# SC32F10T_10G register map
File version: 1.0
CPU: CM0+ r0p1, little endian, MPU, no FPU, 4 interrupt priority bits
Registers are 32-bit, access not given, reset 0x0 unless marked. A register's access mark holds for its fields unless they carry their own. Offsets are from the block's base; [hi:lo] are bit positions.

## WDT
Base 0x40000330
0x0C WDT_CON rw — WDT控制寄存器
  [0] CLRWDT — WDT计数清零位该位通过软件写1，由硬件自动清0。0：无影响1： WDT计数器从0开始计数
0x10 WDT_CFG rw — WDT设置寄存器
  [2:0] WDTCKS — 看门狗时钟选择：WDTCKS[2:0]WDT溢出时间000500ms001250ms010125ms01162.5ms10031.5ms10115.75ms1107.88ms1113.94ms

## IAP
Base 0x400003C0
0x00 IAPKEY — 数据保护寄存器
0x04 IAP_SNB — IAP扇区编号设置寄存器
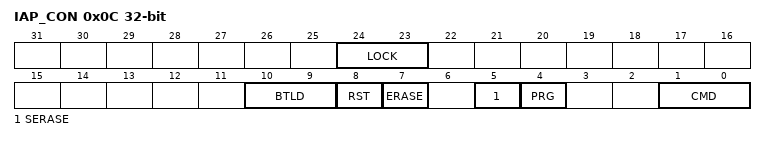
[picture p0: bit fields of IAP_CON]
0x0C IAP_CON rw — IAP控制寄存器
  [24:23] LOCK — 对该位写1后，IAP_CON 寄存器被锁定。当检测到解锁序列时，由硬件将该位清0。如果解锁操作失败，该位仍保持置 1，直到下一次系统复位。
  [10:9] BTLD — 软件复位后程序启动区域选择位：00：芯片软件复位后从APROM（主存储区）启动01：芯片软件复位后从LDROM（系统存储区）启动10：芯片软件复位后从嵌入式SRAM启动11：保留
  [8] RST — 软件复位控制位0：程序正常运行1：对该位写1后系统立刻复位
  [7] ERASE — 全擦（All Erase）控制位0：无操作1：对该位写1后再配置CMD[1:0]=10，则进入APROM全擦除操作，APROM将全部擦除
  [5] SERASE — 扇区擦除（Sector Erase）控制位0：无操作1：对该位写1后再配置CMD[1:0]=10，则进入APROM扇区擦除操作，APROM的指定Sector将被擦除
  [4] PRG — 编程（Program）控制位0：禁止 Flash 编程1：使能 Flash 编程
  [1:0] CMD — IAP命令使能控制位10：执行擦除操作命令其它 : 保留注意：擦除操作命令位写1后，必须配置CMD[1:0]=10，相应的操作才会开始执行一次只能执行1种IAP操作，所以ERASE/SERASE位同一时间只能有一位置1

## CRC
Base 0x40002000
0x00 CRC_DR — CRC数据寄存器
0x04 CRC_CFG — CRC Config register
0x08 CRC_INT — CRC初始值寄存器
0x0C CRC_POL — CRC多项式设置寄存器

## DMA0
Base 0x40010800
Same registers: DMA1 0x40010840, DMA2 0x40010880, DMA3 0x400108C0
0x00 DMA_SADR — DMA 源地址缓存寄存器
0x04 DMA_DADR — DMA 目标地址缓存寄存器
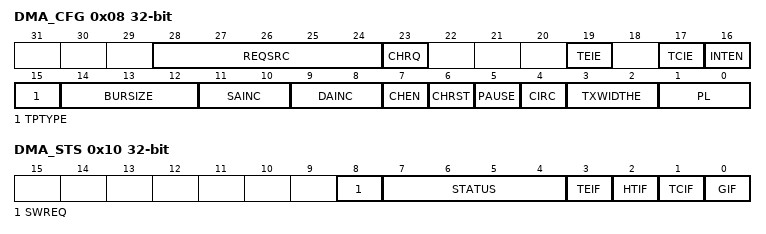
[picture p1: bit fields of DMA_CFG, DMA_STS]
0x08 DMA_CFG rw — DMA 控制/配置寄存器
  [28:24] REQSRC — DMA通道请求源选择位0：禁用当前DMA通道的外设请求选择以下配置值，当前DMA通道的外设请求源将配合设置项中的外设DMA请求使能开关产生：2：UART0_IDE->TXDMAEN3：UART0_IDE->RXDMAEN4：UART1_IDE->TXDMAEN5：UART1_IDE->RXDMAEN12：SPI0_IDE->TXDMAEN13：SPI0_IDE->RXDMAEN14：SPI1_ID
  [23] CHRQ — DMA通道的DMA请求使能位0：禁止，当前DMA通道禁止作为其它DMA通道的请求源1：使能，当前DMA通道可作为其它DMA通道的请求源，即当前DMA通道和其它外设一样，可产生DMA请求。该位使能后，可以实现DMA请求DMA，例如：CHRQ =1，DMA通道n完成数据搬运后，向DMA通道m产生一个DMA请求，通道m响应请求，将预先配置好的参数表更新至通道n的寄存器，从而实现通道n的参数自动更新。
  [19] TEIE — DMA 传输错误中断使能位0：DMA 传输错误中断除能1：DMA 传输错误中断使能
  [17] TCIE — DMA 传输完成中断使能位0：DMA 传输完成中断除能1：DMA 传输完成中断使能
  [16] INTEN — 中断请求 CPU的使能控制位0：禁止中断请求1：使能中断请求
  [15] TPTYPE — DMA通道传输类型选择位0：单次传输1：批量传输。批量传输模式下，DMA控制器搬移DMACNT个数据仅需一次请求，通道响应该请求后，数据将以Burst方式进行传输，即以BURSIZE为单位进行数据搬运直到DMACNT递减为0，一次批量传输模式下的数据处理才算完成。
  [14:12] BURSIZE — 批量传输时，基于 Burst 传输方式下的定义，Burst 大小可选择：000：128001：64010：32011：16100：8101：4110：2111：1
  [11:10] SAINC — DMA通道传输源地址增减模式设置位00: 无增量(固定地址模式)01: 增量模式10: 减量模式11: 递增循环模式 (见DMA传输源地址缓存寄存器)SAINC[1:0]的值可以任意修改，在通道禁止时立即生效；在通道使能时，修改值在循环模式重装载时生效
  [9:8] DAINC — DMA 传输目标地址增减模式设置位00: 无增量(固定地址模式)01: 增量模式10: 减量模式11: 递增循环模式 (见DMA传输目标地址缓存寄存器)DAINC[1:0]的值可以任意修改，在通道禁止时立即生效；在通道使能时，修改值在循环模式重装载时生效
  [7] CHEN — DMA通道使能位0： DMA通道禁止1： DMA通道使能
  [6] CHRST — DMA通道复位控制位，该位用于控制DMA通道复位。0：无效1：当前DMA通道复位。此时，当前DMA通道的CHEN被除能，中断标志为被清除，其他寄存器的值保持不变
  [5] PAUSE — DMA通道传输暂停控制位0：无效1：当前DMA通道暂停。此时，当前DMA通道的CHEN被除能，状态机在完成当前读写周期后回到 state=1，内部寄存器的值处于保持状态(源/目的地址，计数器)，当再次使能当前DMA通道的CHEN时，当前DMA通道的会继续上一次的传输；PAUSE会被写CHEN的动作清0
  [4] CIRC — DMA通道循环模式使能位0：通道未处于循环模式，在达到设定的待传输数据数目时，该通道的DMACNT会保持为零；1：通道处于循环模式，在传输完成后该通道的DMACNT会自动重新装载之前设定的值。循环模式可用于处理循环缓冲区和连续数据流（例如ADC扫描模式）。在循环模式传输过程中，待传输数据的数目将自动重新装载为在通道配置阶段设置的初始值，并继续响应 DMA 请求。为停止循环传输，软件需要在禁止 DM
  [3:2] TXWIDTHE — DMA通道传输宽度选择位选择当前DMA通道的源地址及目标地址每次传输的数据宽度：00：8bit01：16bit10：32bit11：32bitTXWIDTH[1:0] 的值可以任意修改，在通道禁止时，立即生效；在通道打开时，修改值在循环模式重装载时生效。
  [1:0] PL — DMA通道优先级设置位 在 DMA 已经有通道在工作，且其它通道也接收到请求正挂起，当正在工作的通道结束后将启动优先级仲裁。00：低01：中10：高11：非常高注意：同等优先级配置，通道号越小优先级越高。
0x0C DMA_CNT — DMA 计数器缓存寄存器
0x10 DMA_STS rw — DMA 状态寄存器
  [8] SWREQ — DMA通道的软件请求触发位该位写1后，当前DMA通道会一直挂起软件请求，直到当前DMA通道响应，并将该位自动硬件清0。
  [7:4] STATUS — DMA通道状态位0000：空闲。0001：写入源地址0010：读取源地址数据，并写入目的地址0011：写入目的地址数据0100：保留0101：挂起等待中(有通道在忙，其他通道请求挂起)0110：暂停等待中(批量传输模式时PAUSE写1后)0111：burst传输中1000：burst传输停止：PAUSE使能、DMACNT计数到0，或bursize计数到0均会进入此状态
  [3] TEIF — DMA 传输错误中断标志位当DMA读写到未定义的地址时，TEIF会被硬件置1。该位写1清零。
  [2] HTIF — DMA 传输一半中断标志位当DMACNT的计数值计数到DMACNT/2时，HTIF会被硬件置1。该位写1清零。
  [1] TCIF — DMA 传输完成中断标志位当DMACNT的计数值计到0时，TCIF会被硬件置1。该位写1清零。
  [0] GIF — DMA通道全局中断标志位0：当前DMA通道无中断产生1：当前DMA通道产生中断：传输错误、传输到一半或传输完成

## GPIOA — GPIOA peripheral (GPIO_TypeDef)
Base 0x40011000
0x00 PIN — GPIOA,B,C register
0x20 PXCON — GPIO port Control register
0x40 PXPH — GPIO port pull-up/pull-down register
0x60 PXLEV — GPIO port Level register

## GPIOB — GPIOB peripheral (GPIO_TypeDef)
Base 0x40011100
Same registers: GPIOC 0x40011200
0x00 PIN — GPIOA,B,C register
0x20 PXCON — GPIO port Control register
0x40 PXPH — GPIO port pull-up/pull-down register
0x60 PXLEV — GPIO port Level register

## GPIOA_BIT — GPIOA_BIT peripheral (GPIO_BIT_TypeDef)
Base 0x40011000
Same registers: GPIOB_BIT 0x40011000, GPIOC_BIT 0x40011000
0x00 PIN_BIT — GPIOA,B,C Bit register
0x20 PIN_XR — GPIOA,B,C Bit register

## OPT — OPT peripheral (OPT_TypeDef)
Base 0x400003F8
0x00 OPINX — IAP KEY register
0x04 OPREG — IAP Sector Number register
